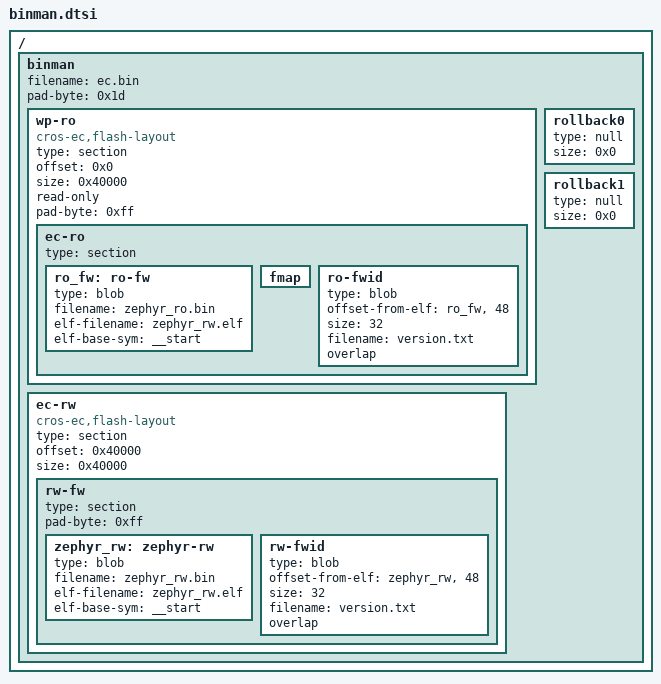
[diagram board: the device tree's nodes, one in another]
/* Copyright 2021 The ChromiumOS Authors
 * Use of this source code is governed by a BSD-style license that can be
 * found in the LICENSE file.
 */

/ {
	#address-cells = <1>;
	#size-cells = <1>;
	binman: binman {
		filename = "ec.bin";
		pad-byte = <0x1d>;
		wp-ro {
			compatible = "cros-ec,flash-layout";
			type = "section";
			offset = <0x0>;
			size = <0x40000>;
			read-only;
			ec-ro {
				type = "section";
				ro_fw: ro-fw {
					type = "blob";
					filename = "zephyr_ro.bin";
					elf-filename = "zephyr_rw.elf";
					elf-base-sym = "__start";
				};
				fmap {
				};
				ro-fwid {
					/* Point the FWID section to
					 * current_image_data.cros_fwid[32].
					 * The offset of cros_fwid is 48.
					 */
					type = "blob";
					offset-from-elf = <&ro_fw>,
						"current_image_data", <48>;
					size = <32>;
					filename = "version.txt";
					overlap;
				};
			};
			pad-byte = <0xff>;
		};

		rollback0 {
			type = "null";
			size = <0x0>;
		};

		rollback1 {
			type = "null";
			size = <0x0>;
		};

		ec-rw {
			compatible = "cros-ec,flash-layout";
			type = "section";
			offset = <0x40000>;
			size = <0x40000>;
			rw-fw {
				type = "section";
				zephyr_rw: zephyr-rw {
					type = "blob";
					filename = "zephyr_rw.bin";
					elf-filename = "zephyr_rw.elf";
					elf-base-sym = "__start";
				};
				rw-fwid {
					/* Point the FWID section to
					 * current_image_data.cros_fwid[32].
					 * The offset of cros_fwid is 48.
					 */
					type = "blob";
					offset-from-elf = <&zephyr_rw>,
						"current_image_data", <48>;
					size = <32>;
					filename = "version.txt";
					overlap;
				};
				pad-byte = <0xff>;
			};
		};
	};
};
